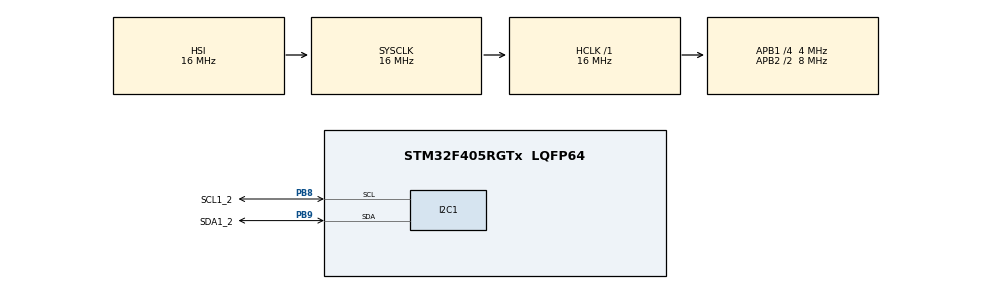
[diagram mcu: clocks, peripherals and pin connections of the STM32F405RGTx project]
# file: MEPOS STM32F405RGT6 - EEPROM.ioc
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Dma.I2C1_RX.0.Direction=DMA_PERIPH_TO_MEMORY
Dma.I2C1_RX.0.FIFOMode=DMA_FIFOMODE_DISABLE
Dma.I2C1_RX.0.Instance=DMA1_Stream0
Dma.I2C1_RX.0.MemDataAlignment=DMA_MDATAALIGN_BYTE
Dma.I2C1_RX.0.MemInc=DMA_MINC_ENABLE
Dma.I2C1_RX.0.Mode=DMA_NORMAL
Dma.I2C1_RX.0.PeriphDataAlignment=DMA_PDATAALIGN_BYTE
Dma.I2C1_RX.0.PeriphInc=DMA_PINC_DISABLE
Dma.I2C1_RX.0.Priority=DMA_PRIORITY_LOW
Dma.I2C1_TX.1.Direction=DMA_MEMORY_TO_PERIPH
Dma.I2C1_TX.1.FIFOMode=DMA_FIFOMODE_DISABLE
Dma.I2C1_TX.1.Instance=DMA1_Stream6
Dma.I2C1_TX.1.MemDataAlignment=DMA_MDATAALIGN_BYTE
Dma.I2C1_TX.1.MemInc=DMA_MINC_ENABLE
Dma.I2C1_TX.1.Mode=DMA_NORMAL
Dma.I2C1_TX.1.PeriphDataAlignment=DMA_PDATAALIGN_BYTE
Dma.I2C1_TX.1.PeriphInc=DMA_PINC_DISABLE
Dma.I2C1_TX.1.Priority=DMA_PRIORITY_LOW
Dma.Request0=I2C1_RX
Dma.Request1=I2C1_TX
I2C1.DualAddressMode=I2C_DUALADDRESS_DISABLE
I2C1.I2C_Mode=I2C_Fast
Mcu.Family=STM32F4
Mcu.Name=STM32F405RGTx
Mcu.Package=LQFP64
NVIC.DMA1_Stream0_IRQn=true\:0\:0\:false\:false\:true\:false\:true\:true
NVIC.DMA1_Stream6_IRQn=true\:0\:0\:false\:false\:true\:false\:true\:true
NVIC.I2C1_ER_IRQn=true\:0\:0\:false\:false\:true\:true\:true\:true
NVIC.I2C1_EV_IRQn=true\:0\:0\:false\:false\:true\:true\:true\:true
NVIC.PriorityGroup=NVIC_PRIORITYGROUP_4
PA13.GPIO_Label=SWDIO
PA13.Mode=Serial_Wire
PA13.Signal=SYS_JTMS-SWDIO
PA14.GPIO_Label=SWCLK
PA14.Mode=Serial_Wire
PA14.Signal=SYS_JTCK-SWCLK
PB8.GPIO_Label=SCL1_2
PB8.Mode=I2C
PB8.Signal=I2C1_SCL
PB9.GPIO_Label=SDA1_2
PB9.Mode=I2C
PB9.Signal=I2C1_SDA
PH0-OSC_IN.Mode=HSE-External-Oscillator
PH0-OSC_IN.Signal=RCC_OSC_IN
PH1-OSC_OUT.Mode=HSE-External-Oscillator
PH1-OSC_OUT.Signal=RCC_OSC_OUT
ProjectManager.HeapSize=0x200
ProjectManager.StackSize=0x400
ProjectManager.TargetToolchain=STM32CubeIDE
RCC.48MHZClocksFreq_Value=96000000
RCC.AHBFreq_Value=16000000
RCC.APB1CLKDivider=RCC_HCLK_DIV4
RCC.APB1Freq_Value=4000000
RCC.APB1TimFreq_Value=8000000
RCC.APB2CLKDivider=RCC_HCLK_DIV2
RCC.APB2Freq_Value=8000000
RCC.APB2TimFreq_Value=16000000
RCC.CortexFreq_Value=16000000
RCC.HCLKFreq_Value=16000000
RCC.HSE_VALUE=16000000
RCC.HSI_VALUE=16000000
RCC.LSE_VALUE=32768
RCC.PLLM=8
RCC.PLLN=336
RCC.PLLQ=7
RCC.PLLSourceVirtual=RCC_PLLSOURCE_HSE
RCC.SYSCLKFreq_VALUE=16000000
RCC.VCOOutputFreq_Value=672000000
board=custom

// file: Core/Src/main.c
/* USER CODE BEGIN Header */
/**
  ******************************************************************************
  * @file           : main.c
  * @brief          : Main program body
  ******************************************************************************
  * @attention
  *
  * Copyright (c) 2022 STMicroelectronics.
  * All rights reserved.
  *
  * This software is licensed under terms that can be found in the LICENSE file
  * in the root directory of this software component.
  * If no LICENSE file comes with this software, it is provided AS-IS.
  *
  ******************************************************************************
  */
/* USER CODE END Header */
#include "main.h"

/* USER CODE BEGIN Includes */
#include "EEPROM.h"

/* USER CODE END Includes */

I2C_HandleTypeDef hi2c1;
DMA_HandleTypeDef hdma_i2c1_rx;
DMA_HandleTypeDef hdma_i2c1_tx;

void SystemClock_Config(void);
static void MX_GPIO_Init(void);
static void MX_DMA_Init(void);
static void MX_I2C1_Init(void);

int main(void)
{

  /* MCU Configuration--------------------------------------------------------*/

  /* Reset of all peripherals, Initializes the Flash interface and the Systick. */
  HAL_Init();

  /* Configure the system clock */
  SystemClock_Config();

  /* Initialize all configured peripherals */
  MX_GPIO_Init();
  MX_DMA_Init();
  MX_I2C1_Init();
  /* USER CODE BEGIN 2 */
  Init_EEPROM(&hi2c1, 0x00);

  Set_Serial_Number(1);			// Temporary should be called once for setup

  /* USER CODE END 2 */

  /* Infinite loop */
  /* USER CODE BEGIN WHILE */
  while (1)
  {
	  Update_On_Time();
    /* USER CODE END WHILE */

  }
}

void SystemClock_Config(void)
{
  RCC_OscInitTypeDef RCC_OscInitStruct = {0};
  RCC_ClkInitTypeDef RCC_ClkInitStruct = {0};

  /** Configure the main internal regulator output voltage
  */
  __HAL_RCC_PWR_CLK_ENABLE();
  __HAL_PWR_VOLTAGESCALING_CONFIG(PWR_REGULATOR_VOLTAGE_SCALE1);

  /** Initializes the RCC Oscillators according to the specified parameters
  * in the RCC_OscInitTypeDef structure.
  */
  RCC_OscInitStruct.OscillatorType = RCC_OSCILLATORTYPE_HSI;
  RCC_OscInitStruct.HSIState = RCC_HSI_ON;
  RCC_OscInitStruct.HSICalibrationValue = RCC_HSICALIBRATION_DEFAULT;
  RCC_OscInitStruct.PLL.PLLState = RCC_PLL_NONE;
  if (HAL_RCC_OscConfig(&RCC_OscInitStruct) != HAL_OK)
  {
    Error_Handler();
  }

  /** Initializes the CPU, AHB and APB buses clocks
  */
  RCC_ClkInitStruct.ClockType = RCC_CLOCKTYPE_HCLK|RCC_CLOCKTYPE_SYSCLK
                              |RCC_CLOCKTYPE_PCLK1|RCC_CLOCKTYPE_PCLK2;
  RCC_ClkInitStruct.SYSCLKSource = RCC_SYSCLKSOURCE_HSI;
  RCC_ClkInitStruct.AHBCLKDivider = RCC_SYSCLK_DIV1;
  RCC_ClkInitStruct.APB1CLKDivider = RCC_HCLK_DIV4;
  RCC_ClkInitStruct.APB2CLKDivider = RCC_HCLK_DIV2;

  if (HAL_RCC_ClockConfig(&RCC_ClkInitStruct, FLASH_LATENCY_0) != HAL_OK)
  {
    Error_Handler();
  }
}

static void MX_I2C1_Init(void)
{

  hi2c1.Instance = I2C1;
  hi2c1.Init.ClockSpeed = 400000;
  hi2c1.Init.DutyCycle = I2C_DUTYCYCLE_2;
  hi2c1.Init.OwnAddress1 = 0;
  hi2c1.Init.AddressingMode = I2C_ADDRESSINGMODE_7BIT;
  hi2c1.Init.DualAddressMode = I2C_DUALADDRESS_DISABLE;
  hi2c1.Init.OwnAddress2 = 0;
  hi2c1.Init.GeneralCallMode = I2C_GENERALCALL_DISABLE;
  hi2c1.Init.NoStretchMode = I2C_NOSTRETCH_DISABLE;
  if (HAL_I2C_Init(&hi2c1) != HAL_OK)
  {
    Error_Handler();
  }

}

static void MX_DMA_Init(void)
{

  /* DMA controller clock enable */
  __HAL_RCC_DMA1_CLK_ENABLE();

  /* DMA interrupt init */
  /* DMA1_Stream0_IRQn interrupt configuration */
  HAL_NVIC_SetPriority(DMA1_Stream0_IRQn, 0, 0);
  HAL_NVIC_EnableIRQ(DMA1_Stream0_IRQn);
  /* DMA1_Stream6_IRQn interrupt configuration */
  HAL_NVIC_SetPriority(DMA1_Stream6_IRQn, 0, 0);
  HAL_NVIC_EnableIRQ(DMA1_Stream6_IRQn);

}

static void MX_GPIO_Init(void)
{

  /* GPIO Ports Clock Enable */
  __HAL_RCC_GPIOH_CLK_ENABLE();
  __HAL_RCC_GPIOA_CLK_ENABLE();
  __HAL_RCC_GPIOB_CLK_ENABLE();

}

void Error_Handler(void)
{
  __disable_irq();
  while (1)
  {
  }
}
